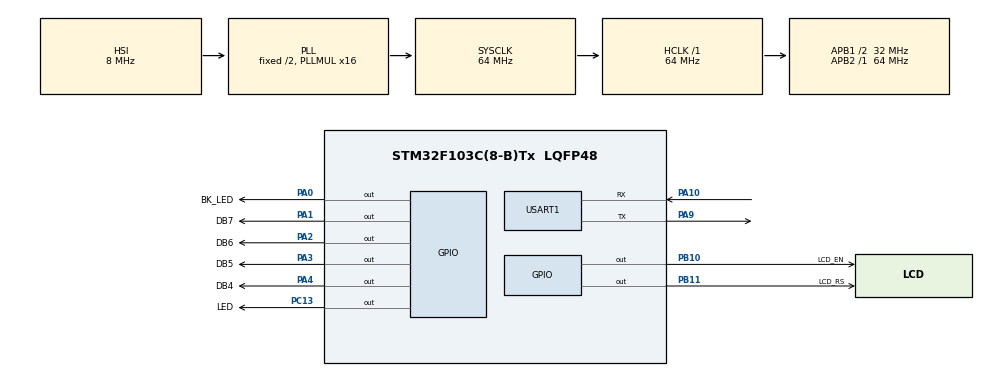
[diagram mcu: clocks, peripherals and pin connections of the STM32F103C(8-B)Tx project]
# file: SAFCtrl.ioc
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Mcu.Family=STM32F1
Mcu.Name=STM32F103C(8-B)Tx
Mcu.Package=LQFP48
NVIC.PriorityGroup=NVIC_PRIORITYGROUP_4
PA0-WKUP.GPIO_Label=BK_LED
PA0-WKUP.GPIO_PuPd=GPIO_PULLUP
PA0-WKUP.PinState=GPIO_PIN_SET
PA0-WKUP.Signal=GPIO_Output
PA1.GPIO_Label=DB7
PA1.GPIO_ModeDefaultOutputPP=GPIO_MODE_OUTPUT_OD
PA1.GPIO_PuPd=GPIO_NOPULL
PA1.GPIO_Speed=GPIO_SPEED_FREQ_MEDIUM
PA1.PinState=GPIO_PIN_SET
PA1.Signal=GPIO_Output
PA10.Mode=Asynchronous
PA10.Signal=USART1_RX
PA13.Mode=Serial_Wire
PA13.Signal=SYS_JTMS-SWDIO
PA14.Mode=Serial_Wire
PA14.Signal=SYS_JTCK-SWCLK
PA2.GPIO_Label=DB6
PA2.GPIO_ModeDefaultOutputPP=GPIO_MODE_OUTPUT_OD
PA2.GPIO_PuPd=GPIO_NOPULL
PA2.GPIO_Speed=GPIO_SPEED_FREQ_MEDIUM
PA2.PinState=GPIO_PIN_SET
PA2.Signal=GPIO_Output
PA3.GPIO_Label=DB5
PA3.GPIO_ModeDefaultOutputPP=GPIO_MODE_OUTPUT_OD
PA3.GPIO_PuPd=GPIO_NOPULL
PA3.GPIO_Speed=GPIO_SPEED_FREQ_MEDIUM
PA3.PinState=GPIO_PIN_SET
PA3.Signal=GPIO_Output
PA4.GPIO_Label=DB4
PA4.GPIO_ModeDefaultOutputPP=GPIO_MODE_OUTPUT_OD
PA4.GPIO_PuPd=GPIO_NOPULL
PA4.GPIO_Speed=GPIO_SPEED_FREQ_MEDIUM
PA4.PinState=GPIO_PIN_SET
PA4.Signal=GPIO_Output
PA9.Mode=Asynchronous
PA9.Signal=USART1_TX
PB10.GPIO_Label=LCD_EN
PB10.GPIO_ModeDefaultOutputPP=GPIO_MODE_OUTPUT_PP
PB10.GPIO_PuPd=GPIO_NOPULL
PB10.GPIO_Speed=GPIO_SPEED_FREQ_MEDIUM
PB10.PinState=GPIO_PIN_SET
PB10.Signal=GPIO_Output
PB11.GPIO_Label=LCD_RS
PB11.GPIO_ModeDefaultOutputPP=GPIO_MODE_OUTPUT_PP
PB11.GPIO_Speed=GPIO_SPEED_FREQ_MEDIUM
PB11.PinState=GPIO_PIN_SET
PB11.Signal=GPIO_Output
PC13-TAMPER-RTC.GPIO_Label=LED
PC13-TAMPER-RTC.GPIO_Speed=GPIO_SPEED_FREQ_MEDIUM
PC13-TAMPER-RTC.PinState=GPIO_PIN_SET
PC13-TAMPER-RTC.Signal=GPIO_Output
ProjectManager.HeapSize=0x200
ProjectManager.StackSize=0x400
ProjectManager.TargetToolchain=Makefile
RCC.AHBFreq_Value=64000000
RCC.APB1CLKDivider=RCC_HCLK_DIV2
RCC.APB1Freq_Value=32000000
RCC.APB1TimFreq_Value=64000000
RCC.APB2Freq_Value=64000000
RCC.APB2TimFreq_Value=64000000
RCC.HCLKFreq_Value=64000000
RCC.PLLMUL=RCC_PLL_MUL16
RCC.SYSCLKFreq_VALUE=64000000
RCC.SYSCLKSource=RCC_SYSCLKSOURCE_PLLCLK
RCC.USBFreq_Value=64000000
USART1.VirtualMode=VM_ASYNC
board=custom

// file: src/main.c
/* USER CODE BEGIN Header */
/**
 ******************************************************************************
 * @file           : main.c
 * @brief          : Main program body
 ******************************************************************************
 * @attention
 *
 * Copyright (c) 2023 STMicroelectronics.
 * All rights reserved.
 *
 * This software is licensed under terms that can be found in the LICENSE file
 * in the root directory of this software component.
 * If no LICENSE file comes with this software, it is provided AS-IS.
 *
 ******************************************************************************
 */
/* USER CODE END Header */
#include "main.h"

UART_HandleTypeDef huart1;

void SystemClock_Config(void);
static void MX_GPIO_Init(void);
static void MX_USART1_UART_Init(void);

int main(void)
{

  /* MCU Configuration--------------------------------------------------------*/

  /* Reset of all peripherals, Initializes the Flash interface and the Systick. */
  HAL_Init();

  /* Configure the system clock */
  SystemClock_Config();

  /* Initialize all configured peripherals */
  MX_GPIO_Init();
  MX_USART1_UART_Init();
  /* USER CODE BEGIN 2 */
  LCDInit();
  LCDXYStr(0,0,"001");
  LCDXYStr(0,1,"002");
  LCDXYStr(0,2,"003");
  LCDXYStr(0,3,"004");
  /* USER CODE END 2 */

  /* Infinite loop */
  while (1)
  {

  }
}

void SystemClock_Config(void)
{
  RCC_OscInitTypeDef RCC_OscInitStruct = {0};
  RCC_ClkInitTypeDef RCC_ClkInitStruct = {0};

  /** Initializes the RCC Oscillators according to the specified parameters
   * in the RCC_OscInitTypeDef structure.
   */
  RCC_OscInitStruct.OscillatorType = RCC_OSCILLATORTYPE_HSI;
  RCC_OscInitStruct.HSIState = RCC_HSI_ON;
  RCC_OscInitStruct.HSICalibrationValue = RCC_HSICALIBRATION_DEFAULT;
  RCC_OscInitStruct.PLL.PLLState = RCC_PLL_ON;
  RCC_OscInitStruct.PLL.PLLSource = RCC_PLLSOURCE_HSI_DIV2;
  RCC_OscInitStruct.PLL.PLLMUL = RCC_PLL_MUL16;
  if (HAL_RCC_OscConfig(&RCC_OscInitStruct) != HAL_OK)
  {
    Error_Handler();
  }

  /** Initializes the CPU, AHB and APB buses clocks
   */
  RCC_ClkInitStruct.ClockType = RCC_CLOCKTYPE_HCLK | RCC_CLOCKTYPE_SYSCLK | RCC_CLOCKTYPE_PCLK1 | RCC_CLOCKTYPE_PCLK2;
  RCC_ClkInitStruct.SYSCLKSource = RCC_SYSCLKSOURCE_PLLCLK;
  RCC_ClkInitStruct.AHBCLKDivider = RCC_SYSCLK_DIV1;
  RCC_ClkInitStruct.APB1CLKDivider = RCC_HCLK_DIV2;
  RCC_ClkInitStruct.APB2CLKDivider = RCC_HCLK_DIV1;

  if (HAL_RCC_ClockConfig(&RCC_ClkInitStruct, FLASH_LATENCY_2) != HAL_OK)
  {
    Error_Handler();
  }
}

static void MX_USART1_UART_Init(void)
{

  huart1.Instance = USART1;
  huart1.Init.BaudRate = 115200;
  huart1.Init.WordLength = UART_WORDLENGTH_8B;
  huart1.Init.StopBits = UART_STOPBITS_1;
  huart1.Init.Parity = UART_PARITY_NONE;
  huart1.Init.Mode = UART_MODE_TX_RX;
  huart1.Init.HwFlowCtl = UART_HWCONTROL_NONE;
  huart1.Init.OverSampling = UART_OVERSAMPLING_16;
  if (HAL_UART_Init(&huart1) != HAL_OK)
  {
    Error_Handler();
  }
}

static void MX_GPIO_Init(void)
{
  GPIO_InitTypeDef GPIO_InitStruct = {0};

  /* GPIO Ports Clock Enable */
  __HAL_RCC_GPIOC_CLK_ENABLE();
  __HAL_RCC_GPIOA_CLK_ENABLE();
  __HAL_RCC_GPIOB_CLK_ENABLE();

  /*Configure GPIO pin Output Level */
  HAL_GPIO_WritePin(LED_GPIO_Port, LED_Pin, GPIO_PIN_SET);

  /*Configure GPIO pin Output Level */
  HAL_GPIO_WritePin(GPIOA, BK_LED_Pin | DB7_Pin | DB6_Pin | DB5_Pin | DB4_Pin, GPIO_PIN_SET);

  /*Configure GPIO pin Output Level */
  HAL_GPIO_WritePin(GPIOB, LCD_EN_Pin | LCD_RS_Pin, GPIO_PIN_SET);

  /*Configure GPIO pin : LED_Pin */
  GPIO_InitStruct.Pin = LED_Pin;
  GPIO_InitStruct.Mode = GPIO_MODE_OUTPUT_PP;
  GPIO_InitStruct.Pull = GPIO_NOPULL;
  GPIO_InitStruct.Speed = GPIO_SPEED_FREQ_MEDIUM;
  HAL_GPIO_Init(LED_GPIO_Port, &GPIO_InitStruct);

  /*Configure GPIO pin : BK_LED_Pin */
  GPIO_InitStruct.Pin = BK_LED_Pin;
  GPIO_InitStruct.Mode = GPIO_MODE_OUTPUT_PP;
  GPIO_InitStruct.Pull = GPIO_PULLUP;
  GPIO_InitStruct.Speed = GPIO_SPEED_FREQ_LOW;
  HAL_GPIO_Init(BK_LED_GPIO_Port, &GPIO_InitStruct);

  /*Configure GPIO pins : DB7_Pin DB6_Pin DB5_Pin DB4_Pin */
  GPIO_InitStruct.Pin = DB7_Pin | DB6_Pin | DB5_Pin | DB4_Pin;
  GPIO_InitStruct.Mode = GPIO_MODE_OUTPUT_OD;
  GPIO_InitStruct.Pull = GPIO_NOPULL;
  GPIO_InitStruct.Speed = GPIO_SPEED_FREQ_MEDIUM;
  HAL_GPIO_Init(GPIOA, &GPIO_InitStruct);

  /*Configure GPIO pins : LCD_EN_Pin LCD_RS_Pin */
  GPIO_InitStruct.Pin = LCD_EN_Pin | LCD_RS_Pin;
  GPIO_InitStruct.Mode = GPIO_MODE_OUTPUT_PP;
  GPIO_InitStruct.Pull = GPIO_NOPULL;
  GPIO_InitStruct.Speed = GPIO_SPEED_FREQ_MEDIUM;
  HAL_GPIO_Init(GPIOB, &GPIO_InitStruct);
}

void Error_Handler(void)
{
  __disable_irq();
  while (1)
  {
  }
}
